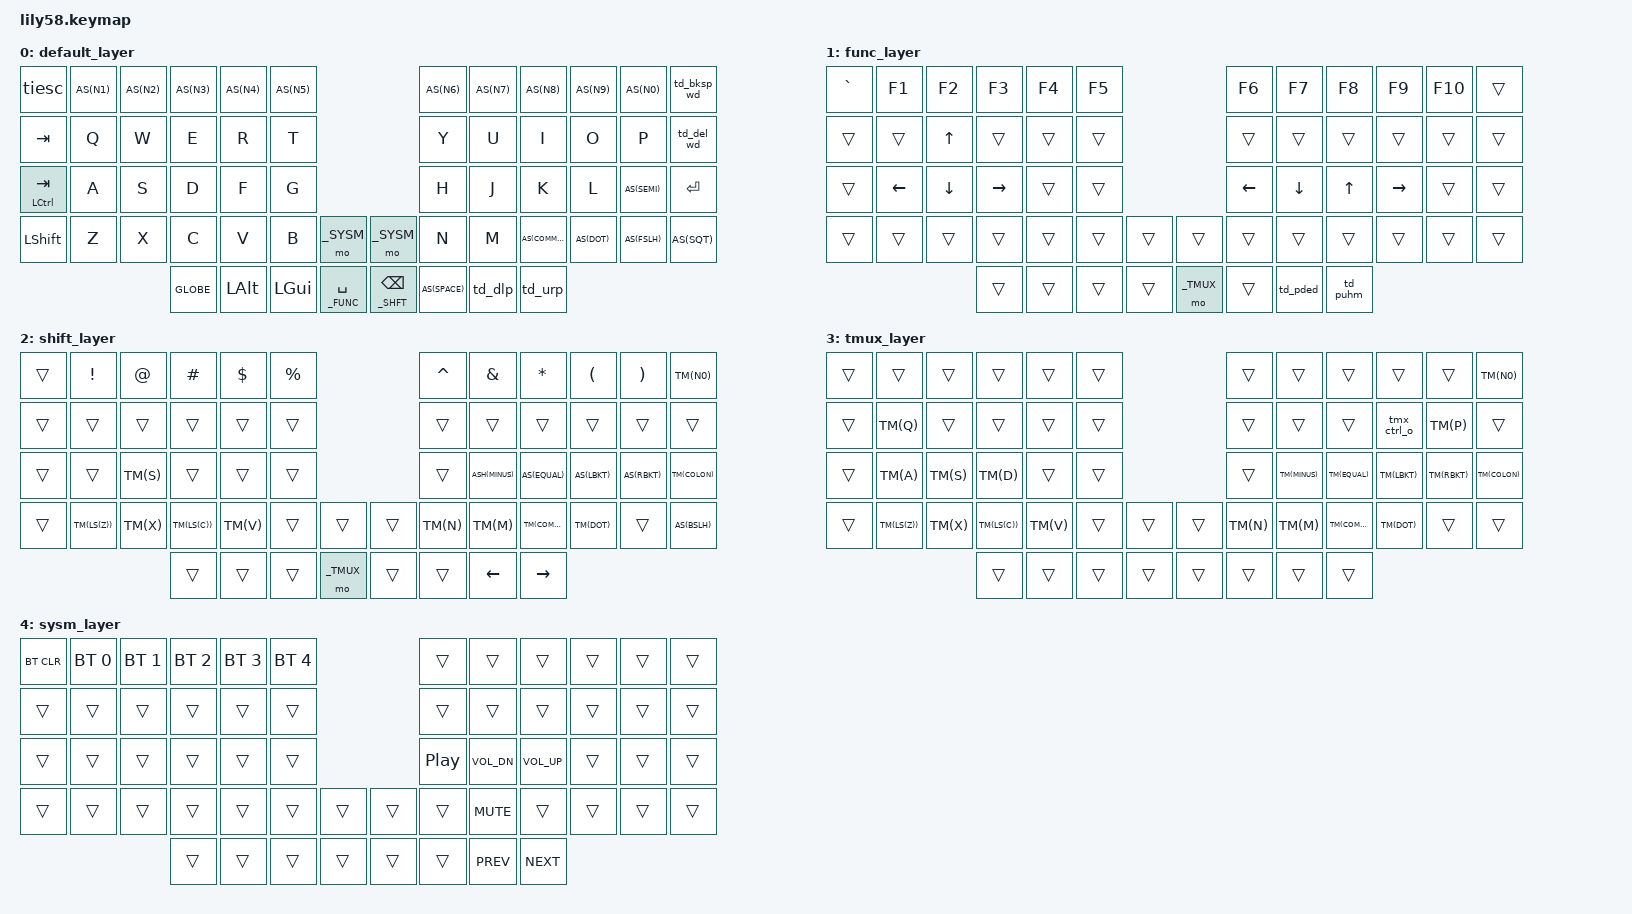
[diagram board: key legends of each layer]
/*
 * Copyright (c) 2020 The ZMK Contributors
 *
 * SPDX-License-Identifier: MIT
 */

#include <behaviors.dtsi>
#include <dt-bindings/zmk/keys.h>
#include <dt-bindings/zmk/bt.h>
#include <dt-bindings/zmk/ext_power.h>


#define _QWERTY 0
#define _FUNC 1
#define _SHFT 2
#define _TMUX 3
#define _SYSM 4

#define AS(keycode) &as LS(keycode) keycode
#define ASH(keycode) &ash LS(keycode) keycode
#define TM(keycode) &tmx keycode

&lt {
    tapping-term-ms = <175>;
};

/* Add this block to the top of your .keymap file */
&kscan0 {
    wakeup-source;
};

/ {
    behaviors {
        ash: auto_shift_hold {
            compatible = "zmk,behavior-hold-tap";
            #binding-cells = <2>;
            tapping_term_ms = <135>;
            quick_tap_ms = <0>;
            flavor = "hold-preferred";
            bindings = <&kp>, <&kp>;
        };
        as: auto_shift {
            compatible = "zmk,behavior-hold-tap";
            #binding-cells = <2>;
            tapping_term_ms = <135>;
            quick_tap_ms = <0>;
            flavor = "tap-preferred";
            bindings = <&kp>, <&kp>;
        };
        td_dlp: tap_dance_dn_lf_pgdn {
            compatible = "zmk,behavior-tap-dance";
            #binding-cells = <0>;
            tapping-term-ms = <200>;
            bindings = <&kp DOWN>, <&kp LEFT>, <&kp PG_DN>;
        };
        td_urp: tap_dance_up_rt_pgup {
            compatible = "zmk,behavior-tap-dance";
            #binding-cells = <0>;
            tapping-term-ms = <200>;
            bindings = <&kp UP>, <&kp RIGHT>, <&kp PG_UP>;
        };
        td_puhm: tap_dance_pg_up_home {
            compatible = "zmk,behavior-tap-dance";
            #binding-cells = <0>;
            tapping-term-ms = <200>;
            bindings = <&kp PG_UP>, <&kp HOME>;
        };
        td_pded: tap_dance_pg_dn_end {
            compatible = "zmk,behavior-tap-dance";
            #binding-cells = <0>;
            tapping-term-ms = <200>;
            bindings = <&kp PG_DN>, <&kp END>;
        };
        tmx: macro_tmux_key {
            compatible = "zmk,behavior-macro-one-param";
            #binding-cells = <1>;
            bindings
                = <&macro_press &kp LCTRL>
                , <&macro_tap &kp A>
                , <&macro_release &kp LCTRL>
                , <&macro_wait_time 50>
                , <&macro_param_1to1>
                , <&macro_tap &kp MACRO_PLACEHOLDER>
                ;
        };
        tmx_ctrl_o: macro_tmux_contrl_o {
            compatible = "zmk,behavior-macro";
            #binding-cells = <0>;
            bindings
                = <&macro_press &kp LCTRL>
                , <&macro_tap &kp A>
                , <&macro_tap &kp O>
                , <&macro_release &kp LCTRL>
                ;
        };
        tiesc: tilde_escape {
            compatible = "zmk,behavior-mod-morph";
            #binding-cells = <0>;
            bindings = <&kp ESC>, <&kp TILDE>;
            mods = <(MOD_LCTL|MOD_LSFT|MOD_LGUI)>;
        };
        wd_del: macro_word_del {
            compatible = "zmk,behavior-macro";
            #binding-cells = <0>;
            bindings
                = <&macro_press &kp LALT>
                , <&macro_tap &kp DEL>
                , <&macro_release &kp LALT>
                ;
        };
        wd_bksp: macro_word_bksp {
            compatible = "zmk,behavior-macro";
            #binding-cells = <0>;
            bindings
                = <&macro_press &kp LALT>
                , <&macro_tap &kp BSPC>
                , <&macro_release &kp LALT>
                ;
        };
        td_bksp_wd: tap_dance_bksp_wd_bksp {
            compatible = "zmk,behavior-tap-dance";
            #binding-cells = <0>;
            tapping-term-ms = <150>;
            bindings = <&kp BSPC>, <&wd_bksp>;
        };
        td_del_wd: tap_dance_del_wd_del {
            compatible = "zmk,behavior-tap-dance";
            #binding-cells = <0>;
            tapping-term-ms = <150>;
            bindings = <&kp DEL>, <&wd_del>;
        };
    };

    keymap {
        compatible = "zmk,keymap";


        default_layer {
/* QWERTY
 *                ,-----------------------------------------.                    ,-----------------------------------------.
 *                | GESC |   1  |   2  |   3  |   4  |   5  |                    |   6  |   7  |   8  |   9  |   0  | Bksp |
 *                |------+------+------+------+------+------|                    |------+------+------+------+------+------|
 *                |  TAB |   Q  |   W  |   E  |   R  |   T  |                    |   Y  |   U  |   I  |   O  |   P  |  Del |
 *                |------+------+------+------+------+------|                    |------+------+------+------+------+------|
 *                |CTL(T)|   A  |   S  |   D  |   F  |   G  |-------.    ,-------|   H  |   J  |   K  |   L  |   ;  | Enter|
 *                |------+------+------+------+------+------|_SYSTM |    |_SYSTM |------+------+------+------+------+------|
 *                |LShift|   Z  |   X  |   C  |   V  |   B  |-------|    |-------|   N  |   M  |   ,  |   .  |   /  |  '   |
 *                `-----------------------------------------/       /     \      \-----------------------------------------'
 *                                  |GLOBE | LAlt | LGUI | /Space  /       \BSPC \  |SPACE | LT/DN | RT/UP|
 *                                  `----------------------------'           '----------------------------'
 */
            bindings = <
&tiesc        AS(N1) AS(N2) AS(N3)    AS(N4)   AS(N5)                                     AS(N6)    AS(N7)   AS(N8)    AS(N9)  AS(N0)   &td_bksp_wd
&kp TAB       &kp Q  &kp W  &kp E     &kp R    &kp T                                      &kp Y     &kp U    &kp I     &kp O   &kp P    &td_del_wd
&mt LCTRL TAB &kp A  &kp S  &kp D     &kp F    &kp G                                      &kp H     &kp J    &kp K     &kp L   AS(SEMI) &kp RET
&kp LSHFT     &kp Z  &kp X  &kp C     &kp V    &kp B     &mo _SYSM        &mo _SYSM       &kp N     &kp M    AS(COMMA) AS(DOT) AS(FSLH) AS(SQT)
                            &kp GLOBE &kp LALT &kp LGUI  &lt _FUNC SPACE  &lt _SHFT BSPC  AS(SPACE) &td_dlp  &td_urp
            >;

        };

        func_layer {
/* FUNCTION
 *        ,-----------------------------------------.                   ,-----------------------------------------.
 *        | TILDE|  F1  |  F2  |  F3  |  F4  |  F5  |                   |  F6  |  F7  |  F8  |  F9  | F10  |      |
 *        |------+------+------+------+------+------|                   |------+------+------+------+------+------|
 *        |      | MB1  |  UP  | MB2  |      |      |                   |      |      |      |      |      |      |
 *        |------+------+------+------+------+------|                   |------+------+------+------+------+------|
 *        | CTL  | LEFT | DOWN | RGHT |      |      |-------.   ,-------| LEFT | DOWN |  UP  | RGHT |      |      |
 *        |------+------+------+------+------+------|       |   |       |------+------+------+------+------+------|
 *        |      |      |      |      |      |      |-------|   |-------|      |      |      |      |      |      |
 *        `-----------------------------------------/       /    \      \-----------------------------------------'
 *                          |      |      |      | /       /      \      \  |RShift| PD/ED| PU/HM|
 *                          `----------------------------'          '------''--------------------'
 */
            bindings = <
&kp GRAVE  &kp F1   &kp F2   &kp F3    &kp F4  &kp F5                     &kp F6   &kp F7    &kp F8    &kp F9    &kp F10  &trans
&trans     &trans   &kp UP   &trans    &trans  &trans                     &trans   &trans    &trans    &trans    &trans   &trans
&trans     &kp LEFT &kp DOWN &kp RIGHT &trans  &trans                     &kp LEFT &kp DOWN  &kp UP    &kp RIGHT &trans   &trans
&trans     &trans   &trans   &trans    &trans  &trans  &trans   &trans    &trans   &trans    &trans    &trans    &trans   &trans
                             &trans    &trans  &trans  &trans   &mo _TMUX &trans   &td_pded &td_puhm
            >;
        };

        shift_layer {
/* SHIFT
 * ,-----------------------------------------.                    ,-----------------------------------------.
 * |      |   !  |   @  |   #  |   $  |   %  |                    |   ^  |   &  |   *  |   (  |   )  |  T-0 |
 * |------+------+------+------+------+------|                    |------+------+------+------+------+------|
 * |      |      |      |      |      |      |                    |      |      |      |      |      |      |
 * |------+------+------+------+------+------|                    |------+------+------+------+------+------|
 * |      |      |  T-S |      |      |      |-------.    ,-------|      |   -  |   =  |   [  |   ]  |  T-: |
 * |------+------+------+------+------+------|       |    |       |------+------+------+------+------+------|
 * |      |  T-Z |  T-X |  T-C |  T-V |      |-------|    |-------|  T-N |  T-M |  T-, |  T-. |      |   \  |
 * `-----------------------------------------/       /     \      \-----------------------------------------'
 *                   |      |      |      | /       /       \      \  |      | LEFT |RIGHT |
 *                   `----------------------------'           '------''--------------------'
 */
            bindings = <
&trans &kp EXCL  &kp AT &kp HASH  &kp DLLR &kp PRCNT                       &kp CARET   &kp AMPS   &kp STAR  &kp LPAR &kp RPAR TM(N0)
&trans &trans    &trans &trans    &trans   &trans                          &trans      &trans     &trans    &trans   &trans   &trans
&trans &trans    TM(S)  &trans    &trans   &trans                          &trans      ASH(MINUS) AS(EQUAL) AS(LBKT) AS(RBKT) TM(COLON)
&trans TM(LS(Z)) TM(X)  TM(LS(C)) TM(V)    &trans    &trans      &trans    TM(N)       TM(M)      TM(COMMA) TM(DOT)  &trans   AS(BSLH)
                       &trans   &trans   &trans    &mo _TMUX   &trans    &trans      &kp LEFT   &kp RIGHT
            >;
        };

        tmux_layer {

/* TMUX
 * ,-----------------------------------------.                    ,-----------------------------------------.
 * |      |      |      |      |      |      |                    |      |      |      |      |      |  T-0 |
 * |------+------+------+------+------+------|                    |------+------+------+------+------+------|
 * |      |  T-Q |      |      |      |      |                    |      |      |      | T-CO |  T-P |      |
 * |------+------+------+------+------+------|                    |------+------+------+------+------+------|
 * |      |  T-A |  T-S |  T-D |      |      |-------.    ,-------|      |  T-- |  T-+ |  T-[ |  T-] | T-:  |
 * |------+------+------+------+------+------|       |    |       |------+------+------+------+------+------|
 * |      |  T-Z |  T-X |  T-C |  T-V |      |-------|    |-------|  T-N |  T-M |  T-, |  T-. |      |      |
 * `-----------------------------------------/       /     \      \-----------------------------------------'
 *                   |      |      |      | /       /       \      \  |      |      |      |
 *                   `----------------------------'           '------''--------------------'
 */
            bindings = <
&trans &trans    &trans &trans    &trans  &trans                       &trans &trans    &trans    &trans      &trans   TM(N0)
&trans TM(Q)     &trans &trans    &trans  &trans                       &trans &trans    &trans    &tmx_ctrl_o TM(P)    &trans
&trans TM(A)     TM(S)  TM(D)     &trans  &trans                       &trans TM(MINUS) TM(EQUAL) TM(LBKT)    TM(RBKT) TM(COLON)
&trans TM(LS(Z)) TM(X)  TM(LS(C)) TM(V)   &trans    &trans   &trans    TM(N)  TM(M)     TM(COMMA) TM(DOT)     &trans   &trans
                     &trans  &trans  &trans    &trans   &trans    &trans &trans    &trans
            >;
        };

        sysm_layer {
/* SYSTEM
 * ,-----------------------------------------.                    ,-----------------------------------------.
 * |BT CLR| BT 0 | BT 1 | BT 2 | BT 3 | BT 4 |                    |      |      |      |      |      |      |
 * |------+------+------+------+------+------|                    +------+------+------+------+------+------|
 * |      |      |      |      |      |      |                    |      |      |      |      |      |      |
 * |------+------+------+------+------+------|                    |------+------+------+------+------+------|
 * |      |      |      |      |      |      |-------.    ,-------|  P/P | Vol- | Vol+ |      |      |      |
 * |------+------+------+------+------+------|       |    |       |------+------+------+------+------+------|
 * |      |      |      |      |      |      |-------|    |-------|      | MUTE |      |      |      |      |
 * `-----------------------------------------/       /     \      \-----------------------------------------'
 *                   |      |      |      | /       /       \      \  |      | MPRV | MNXT |
 *                   `----------------------------'           '------''--------------------'
 */
            bindings = <
&bt BT_CLR &bt BT_SEL 0     &bt BT_SEL 1      &bt BT_SEL 2      &bt BT_SEL 3 &bt BT_SEL 4                 &trans           &trans       &trans       &trans  &trans  &trans
&trans     &trans           &trans            &trans            &trans       &trans                       &trans           &trans       &trans       &trans  &trans  &trans
&trans     &trans           &trans            &trans            &trans       &trans                       &kp C_PLAY_PAUSE &kp K_VOL_DN &kp C_VOL_UP &trans  &trans  &trans
&trans     &trans           &trans            &trans            &trans       &trans    &trans   &trans    &trans           &kp C_MUTE   &trans       &trans  &trans  &trans
                                              &trans            &trans       &trans    &trans   &trans    &trans           &kp C_PREV   &kp C_NEXT
            >;
        };

    };
};

